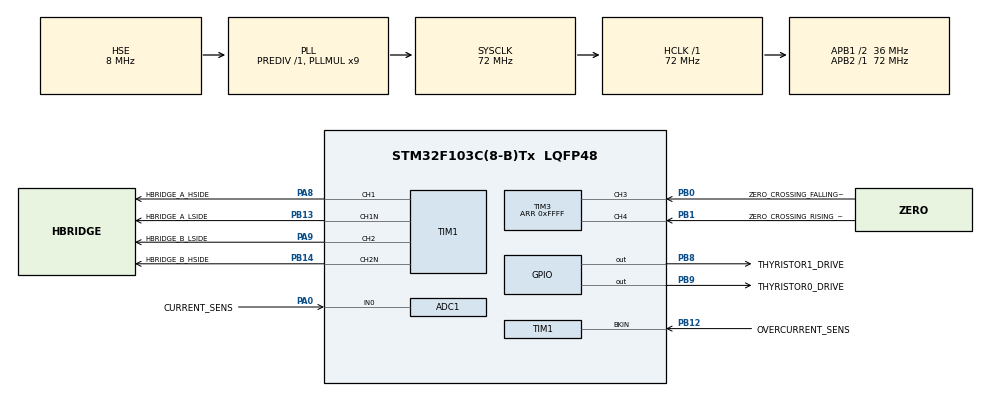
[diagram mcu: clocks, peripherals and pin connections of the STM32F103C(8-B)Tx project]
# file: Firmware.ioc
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ADC1.Channel-0\#ChannelRegularConversion=ADC_CHANNEL_0
ADC1.ExternalTrigConv=ADC_EXTERNALTRIGCONV_T2_CC2
ADC1.NbrOfConversionFlag=1
ADC1.Rank-0\#ChannelRegularConversion=1
ADC1.SamplingTime-0\#ChannelRegularConversion=ADC_SAMPLETIME_7CYCLES_5
ADC1.master=1
Dma.ADC1.0.Direction=DMA_PERIPH_TO_MEMORY
Dma.ADC1.0.Instance=DMA1_Channel1
Dma.ADC1.0.MemDataAlignment=DMA_MDATAALIGN_HALFWORD
Dma.ADC1.0.MemInc=DMA_MINC_ENABLE
Dma.ADC1.0.Mode=DMA_NORMAL
Dma.ADC1.0.PeriphDataAlignment=DMA_PDATAALIGN_HALFWORD
Dma.ADC1.0.PeriphInc=DMA_PINC_DISABLE
Dma.ADC1.0.Priority=DMA_PRIORITY_VERY_HIGH
Dma.Request0=ADC1
Mcu.Family=STM32F1
Mcu.Name=STM32F103C(8-B)Tx
Mcu.Package=LQFP48
Mcu.UserConstants=MCU_CLOCK_FREQ,72000000;DEFAULT_PWM_FREQ,20000;SAMPLES_OVER_PERIOD,8;DEFAULT_LINE_FREQ,50;TIM1_CLOCK_FREQ,MCU_CLOCK_FREQ;TIM1_RELOAD_VALUE,((TIM1_CLOCK_FREQ/DEFAULT_PWM_FREQ)-1);TIM1_PULSE_VALUE,(TIM1_RELOAD_VALUE/2);TIM2_CLOCK_FREQ,MCU_CLOCK_FREQ;TIM2_PRESCALER,0;TIM2_DEFAULT_RELOAD_VALUE,(TIM2_CLOCK_FREQ/(DEFAULT_PWM_FREQ*SAMPLES_OVER_PERIOD));TIM3_CLOCK_FREQ,MCU_CLOCK_FREQ;TIM3_PRESCALER,71;TIM2_OC2_DEFAULT_PULSE_VALUE,(TIM2_DEFAULT_RELOAD_VALUE/2);DEFAULT_SAMPLING_FREQ,(DEFAULT_PWM_FREQ*SAMPLES_OVER_PERIOD);TIM3_RELOAD_VALUE,0xFFFF
NVIC.DMA1_Channel1_IRQn=true\:3\:0\:true\:false\:true\:false\:true
NVIC.PriorityGroup=NVIC_PRIORITYGROUP_4
NVIC.TIM1_BRK_IRQn=true\:2\:0\:true\:false\:true\:true\:true
NVIC.TIM1_UP_IRQn=true\:0\:0\:false\:false\:true\:true\:true
NVIC.TIM3_IRQn=true\:1\:0\:true\:false\:true\:true\:true
PA0-WKUP.GPIO_Label=CURRENT_SENS
PA0-WKUP.Signal=ADCx_IN0
PA13.Mode=Serial_Wire
PA13.Signal=SYS_JTMS-SWDIO
PA14.Mode=Serial_Wire
PA14.Signal=SYS_JTCK-SWCLK
PA8.GPIO_Label=HBRIDGE_A_HSIDE
PA8.GPIO_Speed=GPIO_SPEED_FREQ_MEDIUM
PA8.Signal=S_TIM1_CH1
PA9.GPIO_Label=HBRIDGE_B_LSIDE
PA9.GPIO_Speed=GPIO_SPEED_FREQ_MEDIUM
PA9.Signal=S_TIM1_CH2
PB0.GPIO_Label=ZERO_CROSSING_FALLING_DETECT
PB0.Signal=S_TIM3_CH3
PB1.GPIO_Label=ZERO_CROSSING_RISING_DETECT
PB1.Signal=S_TIM3_CH4
PB12.GPIO_Label=OVERCURRENT_SENS
PB12.Mode=Activate-Break-Input
PB12.Signal=TIM1_BKIN
PB13.GPIO_Label=HBRIDGE_A_LSIDE
PB13.GPIO_Speed=GPIO_SPEED_FREQ_MEDIUM
PB13.Mode=PWM Generation1 CH1 CH1N
PB13.Signal=TIM1_CH1N
PB14.GPIO_Label=HBRIDGE_B_HSIDE
PB14.GPIO_Speed=GPIO_SPEED_FREQ_MEDIUM
PB14.Mode=PWM Generation2 CH2 CH2N
PB14.Signal=TIM1_CH2N
PB8.GPIO_Label=THYRISTOR1_DRIVE
PB8.Signal=GPIO_Output
PB9.GPIO_Label=THYRISTOR0_DRIVE
PB9.Signal=GPIO_Output
PD0-OSC_IN.Mode=HSE-External-Oscillator
PD0-OSC_IN.Signal=RCC_OSC_IN
PD1-OSC_OUT.Mode=HSE-External-Oscillator
PD1-OSC_OUT.Signal=RCC_OSC_OUT
ProjectManager.HeapSize=0x200
ProjectManager.StackSize=0x400
ProjectManager.TargetToolchain=Makefile
RCC.ADCPresc=RCC_ADCPCLK2_DIV6
RCC.AHBFreq_Value=72000000
RCC.APB1CLKDivider=RCC_HCLK_DIV2
RCC.APB1Freq_Value=36000000
RCC.APB1TimFreq_Value=72000000
RCC.APB2Freq_Value=72000000
RCC.APB2TimFreq_Value=72000000
RCC.HCLKFreq_Value=72000000
RCC.PLLMUL=RCC_PLL_MUL9
RCC.PLLSourceVirtual=RCC_PLLSOURCE_HSE
RCC.SYSCLKFreq_VALUE=72000000
RCC.SYSCLKSource=RCC_SYSCLKSOURCE_PLLCLK
RCC.USBFreq_Value=72000000
SH.ADCx_IN0.0=ADC1_IN0,IN0
SH.S_TIM1_CH1.0=TIM1_CH1,PWM Generation1 CH1 CH1N
SH.S_TIM1_CH2.0=TIM1_CH2,PWM Generation2 CH2 CH2N
SH.S_TIM3_CH3.0=TIM3_CH3,Input_Capture3_from_TI3
SH.S_TIM3_CH4.0=TIM3_CH4,Input_Capture4_from_TI4
TIM1.AutoReloadPreload=TIM_AUTORELOAD_PRELOAD_DISABLE
TIM1.AutomaticOutput=TIM_AUTOMATICOUTPUT_ENABLE
TIM1.BreakPolarity=TIM_BREAKPOLARITY_LOW
TIM1.BreakState=TIM_BREAK_ENABLE
TIM1.Channel-PWM\ Generation1\ CH1\ CH1N=TIM_CHANNEL_1
TIM1.Channel-PWM\ Generation2\ CH2\ CH2N=TIM_CHANNEL_2
TIM1.DeadTime=144
TIM1.OCMode_PWM-PWM\ Generation1\ CH1\ CH1N=TIM_OCMODE_PWM2
TIM1.OCMode_PWM-PWM\ Generation2\ CH2\ CH2N=TIM_OCMODE_PWM2
TIM1.OCNIdleState_1=TIM_OCNIDLESTATE_RESET
TIM1.OCNPolarity_1=TIM_OCNPOLARITY_HIGH
TIM1.OCNPolarity_2=TIM_OCNPOLARITY_HIGH
TIM1.OCPolarity_1=TIM_OCPOLARITY_HIGH
TIM1.OCPolarity_2=TIM_OCPOLARITY_HIGH
TIM1.OffStateRunMode=TIM_OSSR_DISABLE
TIM1.Period=TIM1_RELOAD_VALUE
TIM1.TIM_MasterOutputTrigger=TIM_TRGO_UPDATE
TIM2.Channel-PWM\ Generation2\ No\ Output=TIM_CHANNEL_2
TIM2.OCMode_PWM-PWM\ Generation2\ No\ Output=TIM_OCMODE_PWM2
TIM2.Period=TIM2_DEFAULT_RELOAD_VALUE
TIM2.Pulse-PWM\ Generation2\ No\ Output=TIM2_OC2_DEFAULT_PULSE_VALUE
TIM2.TIM_MasterOutputTrigger=TIM_TRGO_OC2REF
TIM2.TIM_MasterSlaveMode=TIM_MASTERSLAVEMODE_DISABLE
TIM3.AutoReloadPreload=TIM_AUTORELOAD_PRELOAD_DISABLE
TIM3.Channel-Input_Capture3_from_TI3=TIM_CHANNEL_3
TIM3.Channel-Input_Capture4_from_TI4=TIM_CHANNEL_4
TIM3.Channel-Output\ Compare1\ No\ Output=TIM_CHANNEL_1
TIM3.Channel-Output\ Compare2\ No\ Output=TIM_CHANNEL_2
TIM3.ICFilter_CH3=15
TIM3.ICFilter_CH4=15
TIM3.ICPolarity_CH3=TIM_INPUTCHANNELPOLARITY_FALLING
TIM3.ICPolarity_CH4=TIM_INPUTCHANNELPOLARITY_RISING
TIM3.Period=0xFFFF
TIM3.Prescaler=TIM3_PRESCALER
VP_TIM1_VS_ClockSourceINT.Mode=Internal
VP_TIM2_VS_ClockSourceINT.Mode=Internal
VP_TIM2_VS_ClockSourceITR.Mode=TriggerSource_ITR0
VP_TIM2_VS_ControllerModeReset.Mode=Reset Mode
VP_TIM2_VS_no_output2.Mode=PWM Generation2 No Output
VP_TIM3_VS_ClockSourceINT.Mode=Internal
VP_TIM3_VS_no_output1.Mode=Output Compare1 No Output
VP_TIM3_VS_no_output2.Mode=Output Compare2 No Output
VP_TIM4_VS_ClockSourceINT.Mode=Internal
board=custom

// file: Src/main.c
/* USER CODE BEGIN Header */
/**
  ******************************************************************************
  * @file           : main.c
  * @brief          : Main program body
  ******************************************************************************
  * @attention
  *
  * <h2><center>&copy; Copyright (c) 2020 STMicroelectronics.
  * All rights reserved.</center></h2>
  *
  * This software component is licensed by ST under BSD 3-Clause license,
  * the "License"; You may not use this file except in compliance with the
  * License. You may obtain a copy of the License at:
  *                        opensource.org/licenses/BSD-3-Clause
  *
  ******************************************************************************
  */
/* USER CODE END Header */

#include "main.h"

/* USER CODE BEGIN Includes */
#include "lattice.h"
/* USER CODE END Includes */

ADC_HandleTypeDef hadc1;
DMA_HandleTypeDef hdma_adc1;

TIM_HandleTypeDef htim1;
TIM_HandleTypeDef htim2;
TIM_HandleTypeDef htim3;
TIM_HandleTypeDef htim4;

void SystemClock_Config(void);
static void MX_GPIO_Init(void);
static void MX_DMA_Init(void);
static void MX_TIM1_Init(void);
static void MX_TIM3_Init(void);
static void MX_ADC1_Init(void);
static void MX_TIM2_Init(void);
static void MX_TIM4_Init(void);

int main(void)
{

  /* MCU Configuration--------------------------------------------------------*/

  /* Reset of all peripherals, Initializes the Flash interface and the Systick. */
  HAL_Init();

  /* Configure the system clock */
  SystemClock_Config();

  /* Initialize all configured peripherals */
  MX_GPIO_Init();
  MX_DMA_Init();
  MX_TIM1_Init();
  MX_TIM3_Init();
  MX_ADC1_Init();
  MX_TIM2_Init();
  MX_TIM4_Init();
  /* USER CODE BEGIN 2 */
  // Wait some time for stabilization of the board.
  Lattice_Start();
  /* USER CODE END 2 */

  /* Infinite loop */
  /* USER CODE BEGIN WHILE */
  while (1)
  {
    Lattice_Execute();
    /* USER CODE END WHILE */

  }
}

void SystemClock_Config(void)
{
  RCC_OscInitTypeDef RCC_OscInitStruct = {0};
  RCC_ClkInitTypeDef RCC_ClkInitStruct = {0};
  RCC_PeriphCLKInitTypeDef PeriphClkInit = {0};

  /** Initializes the CPU, AHB and APB busses clocks
  */
  RCC_OscInitStruct.OscillatorType = RCC_OSCILLATORTYPE_HSE;
  RCC_OscInitStruct.HSEState = RCC_HSE_ON;
  RCC_OscInitStruct.HSEPredivValue = RCC_HSE_PREDIV_DIV1;
  RCC_OscInitStruct.HSIState = RCC_HSI_ON;
  RCC_OscInitStruct.PLL.PLLState = RCC_PLL_ON;
  RCC_OscInitStruct.PLL.PLLSource = RCC_PLLSOURCE_HSE;
  RCC_OscInitStruct.PLL.PLLMUL = RCC_PLL_MUL9;
  if (HAL_RCC_OscConfig(&RCC_OscInitStruct) != HAL_OK)
  {
    Error_Handler();
  }
  /** Initializes the CPU, AHB and APB busses clocks
  */
  RCC_ClkInitStruct.ClockType = RCC_CLOCKTYPE_HCLK|RCC_CLOCKTYPE_SYSCLK
                              |RCC_CLOCKTYPE_PCLK1|RCC_CLOCKTYPE_PCLK2;
  RCC_ClkInitStruct.SYSCLKSource = RCC_SYSCLKSOURCE_PLLCLK;
  RCC_ClkInitStruct.AHBCLKDivider = RCC_SYSCLK_DIV1;
  RCC_ClkInitStruct.APB1CLKDivider = RCC_HCLK_DIV2;
  RCC_ClkInitStruct.APB2CLKDivider = RCC_HCLK_DIV1;

  if (HAL_RCC_ClockConfig(&RCC_ClkInitStruct, FLASH_LATENCY_2) != HAL_OK)
  {
    Error_Handler();
  }
  PeriphClkInit.PeriphClockSelection = RCC_PERIPHCLK_ADC;
  PeriphClkInit.AdcClockSelection = RCC_ADCPCLK2_DIV6;
  if (HAL_RCCEx_PeriphCLKConfig(&PeriphClkInit) != HAL_OK)
  {
    Error_Handler();
  }
}

static void MX_ADC1_Init(void)
{

  ADC_ChannelConfTypeDef sConfig = {0};

  /** Common config
  */
  hadc1.Instance = ADC1;
  hadc1.Init.ScanConvMode = ADC_SCAN_DISABLE;
  hadc1.Init.ContinuousConvMode = DISABLE;
  hadc1.Init.DiscontinuousConvMode = DISABLE;
  hadc1.Init.ExternalTrigConv = ADC_EXTERNALTRIGCONV_T2_CC2;
  hadc1.Init.DataAlign = ADC_DATAALIGN_RIGHT;
  hadc1.Init.NbrOfConversion = 1;
  if (HAL_ADC_Init(&hadc1) != HAL_OK)
  {
    Error_Handler();
  }
  /** Configure Regular Channel
  */
  sConfig.Channel = ADC_CHANNEL_0;
  sConfig.Rank = ADC_REGULAR_RANK_1;
  sConfig.SamplingTime = ADC_SAMPLETIME_7CYCLES_5;
  if (HAL_ADC_ConfigChannel(&hadc1, &sConfig) != HAL_OK)
  {
    Error_Handler();
  }

}

static void MX_TIM1_Init(void)
{

  TIM_ClockConfigTypeDef sClockSourceConfig = {0};
  TIM_MasterConfigTypeDef sMasterConfig = {0};
  TIM_OC_InitTypeDef sConfigOC = {0};
  TIM_BreakDeadTimeConfigTypeDef sBreakDeadTimeConfig = {0};

  htim1.Instance = TIM1;
  htim1.Init.Prescaler = 0;
  htim1.Init.CounterMode = TIM_COUNTERMODE_UP;
  htim1.Init.Period = TIM1_RELOAD_VALUE;
  htim1.Init.ClockDivision = TIM_CLOCKDIVISION_DIV1;
  htim1.Init.RepetitionCounter = 0;
  htim1.Init.AutoReloadPreload = TIM_AUTORELOAD_PRELOAD_DISABLE;
  if (HAL_TIM_Base_Init(&htim1) != HAL_OK)
  {
    Error_Handler();
  }
  sClockSourceConfig.ClockSource = TIM_CLOCKSOURCE_INTERNAL;
  if (HAL_TIM_ConfigClockSource(&htim1, &sClockSourceConfig) != HAL_OK)
  {
    Error_Handler();
  }
  if (HAL_TIM_PWM_Init(&htim1) != HAL_OK)
  {
    Error_Handler();
  }
  sMasterConfig.MasterOutputTrigger = TIM_TRGO_UPDATE;
  sMasterConfig.MasterSlaveMode = TIM_MASTERSLAVEMODE_DISABLE;
  if (HAL_TIMEx_MasterConfigSynchronization(&htim1, &sMasterConfig) != HAL_OK)
  {
    Error_Handler();
  }
  sConfigOC.OCMode = TIM_OCMODE_PWM2;
  sConfigOC.Pulse = 0;
  sConfigOC.OCPolarity = TIM_OCPOLARITY_HIGH;
  sConfigOC.OCNPolarity = TIM_OCNPOLARITY_HIGH;
  sConfigOC.OCFastMode = TIM_OCFAST_DISABLE;
  sConfigOC.OCIdleState = TIM_OCIDLESTATE_RESET;
  sConfigOC.OCNIdleState = TIM_OCNIDLESTATE_RESET;
  if (HAL_TIM_PWM_ConfigChannel(&htim1, &sConfigOC, TIM_CHANNEL_1) != HAL_OK)
  {
    Error_Handler();
  }
  if (HAL_TIM_PWM_ConfigChannel(&htim1, &sConfigOC, TIM_CHANNEL_2) != HAL_OK)
  {
    Error_Handler();
  }
  sBreakDeadTimeConfig.OffStateRunMode = TIM_OSSR_DISABLE;
  sBreakDeadTimeConfig.OffStateIDLEMode = TIM_OSSI_DISABLE;
  sBreakDeadTimeConfig.LockLevel = TIM_LOCKLEVEL_OFF;
  sBreakDeadTimeConfig.DeadTime = 144;
  sBreakDeadTimeConfig.BreakState = TIM_BREAK_ENABLE;
  sBreakDeadTimeConfig.BreakPolarity = TIM_BREAKPOLARITY_LOW;
  sBreakDeadTimeConfig.AutomaticOutput = TIM_AUTOMATICOUTPUT_ENABLE;
  if (HAL_TIMEx_ConfigBreakDeadTime(&htim1, &sBreakDeadTimeConfig) != HAL_OK)
  {
    Error_Handler();
  }
  HAL_TIM_MspPostInit(&htim1);

}

static void MX_TIM2_Init(void)
{

  TIM_ClockConfigTypeDef sClockSourceConfig = {0};
  TIM_SlaveConfigTypeDef sSlaveConfig = {0};
  TIM_MasterConfigTypeDef sMasterConfig = {0};
  TIM_OC_InitTypeDef sConfigOC = {0};

  htim2.Instance = TIM2;
  htim2.Init.Prescaler = 0;
  htim2.Init.CounterMode = TIM_COUNTERMODE_UP;
  htim2.Init.Period = TIM2_DEFAULT_RELOAD_VALUE;
  htim2.Init.ClockDivision = TIM_CLOCKDIVISION_DIV1;
  htim2.Init.AutoReloadPreload = TIM_AUTORELOAD_PRELOAD_DISABLE;
  if (HAL_TIM_Base_Init(&htim2) != HAL_OK)
  {
    Error_Handler();
  }
  sClockSourceConfig.ClockSource = TIM_CLOCKSOURCE_INTERNAL;
  if (HAL_TIM_ConfigClockSource(&htim2, &sClockSourceConfig) != HAL_OK)
  {
    Error_Handler();
  }
  if (HAL_TIM_PWM_Init(&htim2) != HAL_OK)
  {
    Error_Handler();
  }
  sSlaveConfig.SlaveMode = TIM_SLAVEMODE_RESET;
  sSlaveConfig.InputTrigger = TIM_TS_ITR0;
  if (HAL_TIM_SlaveConfigSynchronization(&htim2, &sSlaveConfig) != HAL_OK)
  {
    Error_Handler();
  }
  sMasterConfig.MasterOutputTrigger = TIM_TRGO_OC2REF;
  sMasterConfig.MasterSlaveMode = TIM_MASTERSLAVEMODE_DISABLE;
  if (HAL_TIMEx_MasterConfigSynchronization(&htim2, &sMasterConfig) != HAL_OK)
  {
    Error_Handler();
  }
  sConfigOC.OCMode = TIM_OCMODE_PWM2;
  sConfigOC.Pulse = TIM2_OC2_DEFAULT_PULSE_VALUE;
  sConfigOC.OCPolarity = TIM_OCPOLARITY_HIGH;
  sConfigOC.OCFastMode = TIM_OCFAST_DISABLE;
  if (HAL_TIM_PWM_ConfigChannel(&htim2, &sConfigOC, TIM_CHANNEL_2) != HAL_OK)
  {
    Error_Handler();
  }

}

static void MX_TIM3_Init(void)
{

  TIM_ClockConfigTypeDef sClockSourceConfig = {0};
  TIM_MasterConfigTypeDef sMasterConfig = {0};
  TIM_OC_InitTypeDef sConfigOC = {0};
  TIM_IC_InitTypeDef sConfigIC = {0};

  htim3.Instance = TIM3;
  htim3.Init.Prescaler = TIM3_PRESCALER;
  htim3.Init.CounterMode = TIM_COUNTERMODE_UP;
  htim3.Init.Period = 0xFFFF;
  htim3.Init.ClockDivision = TIM_CLOCKDIVISION_DIV1;
  htim3.Init.AutoReloadPreload = TIM_AUTORELOAD_PRELOAD_DISABLE;
  if (HAL_TIM_Base_Init(&htim3) != HAL_OK)
  {
    Error_Handler();
  }
  sClockSourceConfig.ClockSource = TIM_CLOCKSOURCE_INTERNAL;
  if (HAL_TIM_ConfigClockSource(&htim3, &sClockSourceConfig) != HAL_OK)
  {
    Error_Handler();
  }
  if (HAL_TIM_OC_Init(&htim3) != HAL_OK)
  {
    Error_Handler();
  }
  if (HAL_TIM_IC_Init(&htim3) != HAL_OK)
  {
    Error_Handler();
  }
  sMasterConfig.MasterOutputTrigger = TIM_TRGO_RESET;
  sMasterConfig.MasterSlaveMode = TIM_MASTERSLAVEMODE_DISABLE;
  if (HAL_TIMEx_MasterConfigSynchronization(&htim3, &sMasterConfig) != HAL_OK)
  {
    Error_Handler();
  }
  sConfigOC.OCMode = TIM_OCMODE_TIMING;
  sConfigOC.Pulse = 0;
  sConfigOC.OCPolarity = TIM_OCPOLARITY_HIGH;
  sConfigOC.OCFastMode = TIM_OCFAST_DISABLE;
  if (HAL_TIM_OC_ConfigChannel(&htim3, &sConfigOC, TIM_CHANNEL_1) != HAL_OK)
  {
    Error_Handler();
  }
  if (HAL_TIM_OC_ConfigChannel(&htim3, &sConfigOC, TIM_CHANNEL_2) != HAL_OK)
  {
    Error_Handler();
  }
  sConfigIC.ICPolarity = TIM_INPUTCHANNELPOLARITY_FALLING;
  sConfigIC.ICSelection = TIM_ICSELECTION_DIRECTTI;
  sConfigIC.ICPrescaler = TIM_ICPSC_DIV1;
  sConfigIC.ICFilter = 15;
  if (HAL_TIM_IC_ConfigChannel(&htim3, &sConfigIC, TIM_CHANNEL_3) != HAL_OK)
  {
    Error_Handler();
  }
  sConfigIC.ICPolarity = TIM_INPUTCHANNELPOLARITY_RISING;
  if (HAL_TIM_IC_ConfigChannel(&htim3, &sConfigIC, TIM_CHANNEL_4) != HAL_OK)
  {
    Error_Handler();
  }

}

static void MX_TIM4_Init(void)
{

  TIM_ClockConfigTypeDef sClockSourceConfig = {0};
  TIM_MasterConfigTypeDef sMasterConfig = {0};

  htim4.Instance = TIM4;
  htim4.Init.Prescaler = 0;
  htim4.Init.CounterMode = TIM_COUNTERMODE_UP;
  htim4.Init.Period = 0;
  htim4.Init.ClockDivision = TIM_CLOCKDIVISION_DIV1;
  htim4.Init.AutoReloadPreload = TIM_AUTORELOAD_PRELOAD_DISABLE;
  if (HAL_TIM_Base_Init(&htim4) != HAL_OK)
  {
    Error_Handler();
  }
  sClockSourceConfig.ClockSource = TIM_CLOCKSOURCE_INTERNAL;
  if (HAL_TIM_ConfigClockSource(&htim4, &sClockSourceConfig) != HAL_OK)
  {
    Error_Handler();
  }
  sMasterConfig.MasterOutputTrigger = TIM_TRGO_RESET;
  sMasterConfig.MasterSlaveMode = TIM_MASTERSLAVEMODE_DISABLE;
  if (HAL_TIMEx_MasterConfigSynchronization(&htim4, &sMasterConfig) != HAL_OK)
  {
    Error_Handler();
  }

}

static void MX_DMA_Init(void)
{
  /* DMA controller clock enable */
  __HAL_RCC_DMA1_CLK_ENABLE();

  /* DMA interrupt init */
  /* DMA1_Channel1_IRQn interrupt configuration */
  HAL_NVIC_SetPriority(DMA1_Channel1_IRQn, 3, 0);
  HAL_NVIC_EnableIRQ(DMA1_Channel1_IRQn);

}

static void MX_GPIO_Init(void)
{
  GPIO_InitTypeDef GPIO_InitStruct = {0};

  /* GPIO Ports Clock Enable */
  __HAL_RCC_GPIOD_CLK_ENABLE();
  __HAL_RCC_GPIOA_CLK_ENABLE();
  __HAL_RCC_GPIOB_CLK_ENABLE();

  /*Configure GPIO pin Output Level */
  HAL_GPIO_WritePin(GPIOB, THYRISTOR0_DRIVE_Pin|THYRISTOR1_DRIVE_Pin, GPIO_PIN_RESET);

  /*Configure GPIO pins : THYRISTOR0_DRIVE_Pin THYRISTOR1_DRIVE_Pin */
  GPIO_InitStruct.Pin = THYRISTOR0_DRIVE_Pin|THYRISTOR1_DRIVE_Pin;
  GPIO_InitStruct.Mode = GPIO_MODE_OUTPUT_PP;
  GPIO_InitStruct.Pull = GPIO_NOPULL;
  GPIO_InitStruct.Speed = GPIO_SPEED_FREQ_LOW;
  HAL_GPIO_Init(GPIOB, &GPIO_InitStruct);

}

void Error_Handler(void)
{
}

/************************ (C) COPYRIGHT STMicroelectronics *****END OF FILE****/
